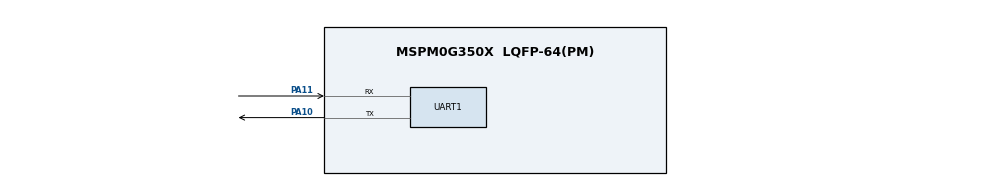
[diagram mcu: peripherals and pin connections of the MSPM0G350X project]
/**
 * @cliArgs --device "MSPM0G350X" --part "Default" --package "LQFP-64(PM)" --product "mspm0_sdk@2.04.00.06"
 * @versions {"tool":"1.22.0+3893"}
 */

/**
 * Import the modules used in this configuration.
 */
const GPIO  = scripting.addModule("/ti/driverlib/GPIO", {}, false);
const GPIO1 = GPIO.addInstance();
const GPIO2 = GPIO.addInstance();
const GPIO3 = GPIO.addInstance();
const UART  = scripting.addModule("/ti/driverlib/UART", {}, false);
const UART1 = UART.addInstance();
const UART2 = UART.addInstance();

/**
 * Write custom configuration values to the imported modules.
 */
GPIO1.$name                               = "LEDS";
GPIO1.associatedPins.create(3);
GPIO1.associatedPins[0].initialValue      = "SET";
GPIO1.associatedPins[0].$name             = "RED";
GPIO1.associatedPins[0].launchPadShortcut = "LED2RedEn";
GPIO1.associatedPins[1].initialValue      = "SET";
GPIO1.associatedPins[1].$name             = "BLUE";
GPIO1.associatedPins[1].launchPadShortcut = "LED2BlueEn";
GPIO1.associatedPins[2].$name             = "GREEN";
GPIO1.associatedPins[2].launchPadShortcut = "LED2GreenEn";

const Board           = scripting.addModule("/ti/driverlib/Board", {}, false);
Board.configureUnused = true;

GPIO2.$name                               = "MONO";
GPIO2.associatedPins[0].launchPadShortcut = "LED1En";
GPIO2.associatedPins[0].$name             = "LIGHT";

GPIO3.$name                          = "SENSOR";
GPIO3.associatedPins[0].$name        = "TEMP";
GPIO3.associatedPins[0].assignedPort = "PORTB";
GPIO3.associatedPins[0].assignedPin  = "4";

const SYSCTL                 = scripting.addModule("/ti/driverlib/SYSCTL", {}, false);
SYSCTL.powerPolicy           = "STANDBY0";
SYSCTL.forceDefaultClkConfig = true;
SYSCTL.clockTreeEn           = true;

UART1.$name                    = "UART_0";
UART1.rxFifoThreshold          = "DL_UART_RX_FIFO_LEVEL_ONE_ENTRY";
UART1.enableDMARX              = false;
UART1.enableDMATX              = false;
UART1.uartClkSrc               = "LFCLK";
UART1.ovsRate                  = "3";
UART1.enabledInterrupts        = ["RX"];
UART1.interruptPriority        = "0";
UART1.peripheral.$assign       = "UART0";
UART1.peripheral.rxPin.$assign = "PA11";
UART1.peripheral.txPin.$assign = "PA10";
UART1.txPinConfig.$name        = "ti_driverlib_gpio_GPIOPinGeneric0";
UART1.rxPinConfig.$name        = "ti_driverlib_gpio_GPIOPinGeneric1";

UART2.enabledInterrupts                = ["RX"];
UART2.$name                            = "BLE";
UART2.txPinConfig.$name                = "ti_driverlib_gpio_GPIOPinGeneric2";
UART2.txPinConfig.direction            = scripting.forceWrite("OUTPUT");
UART2.txPinConfig.hideOutputInversion  = scripting.forceWrite(false);
UART2.txPinConfig.onlyInternalResistor = scripting.forceWrite(false);
UART2.txPinConfig.passedPeripheralType = scripting.forceWrite("Digital");
UART2.rxPinConfig.$name                = "ti_driverlib_gpio_GPIOPinGeneric3";
UART2.rxPinConfig.hideOutputInversion  = scripting.forceWrite(false);
UART2.rxPinConfig.onlyInternalResistor = scripting.forceWrite(false);
UART2.rxPinConfig.passedPeripheralType = scripting.forceWrite("Digital");

/**
 * Pinmux solution for unlocked pins/peripherals. This ensures that minor changes to the automatic solver in a future
 * version of the tool will not impact the pinmux you originally saw.  These lines can be completely deleted in order to
 * re-solve from scratch.
 */
GPIO1.associatedPins[0].pin.$suggestSolution = "PB26";
GPIO1.associatedPins[1].pin.$suggestSolution = "PB22";
GPIO1.associatedPins[2].pin.$suggestSolution = "PB27";
Board.peripheral.$suggestSolution            = "DEBUGSS";
Board.peripheral.swclkPin.$suggestSolution   = "PA20";
Board.peripheral.swdioPin.$suggestSolution   = "PA19";
GPIO2.associatedPins[0].pin.$suggestSolution = "PA0";
GPIO3.associatedPins[0].pin.$suggestSolution = "PB4";
UART2.peripheral.$suggestSolution            = "UART1";
UART2.peripheral.rxPin.$suggestSolution      = "PA18";
UART2.peripheral.txPin.$suggestSolution      = "PA17";
